AUTOSAR XML (schema 00046)
package /ComponentTypes
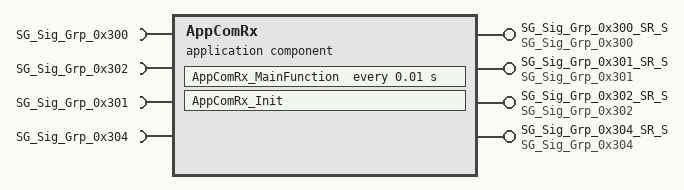
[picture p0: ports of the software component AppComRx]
  application sw component type AppComRx
    4 x require port:
      SG_Sig_Grp_0x300: nonqueued-receiver-com-spec{data-element=SG_Sig_Grp_0x300, init-value=fields=[D_Led1_Control:2, D_Led2_Control:2, D_Led3_Control:2, D_Led4_Control:2, SupD_Checksum_0x300:0, SupD_Counter_0x300:0]}, required-interface=SG_Sig_Grp_0x300
      SG_Sig_Grp_0x302: nonqueued-receiver-com-spec{data-element=SG_Sig_Grp_0x302, init-value=fields=[E_Sig_0x302_Used_1:0, E_Sig_0x302_Used_2:0, E_Sig_0x302_Used_3:0]}, required-interface=SG_Sig_Grp_0x302
      SG_Sig_Grp_0x301: nonqueued-receiver-com-spec{data-element=SG_Sig_Grp_0x301, init-value=fields=[D_Button1_Control:0, D_Button2_Control:0, D_Button3_Control:0, D_Button4_Control:0]}, required-interface=SG_Sig_Grp_0x301
      SG_Sig_Grp_0x304: nonqueued-receiver-com-spec{data-element=SG_Sig_Grp_0x304, init-value=fields=[D_Led1_CtrlMode:0, D_Led2_CtrlMode:0, D_Led3_CtrlMode:0, D_Led4_CtrlMode:0, SupD_Checksum_0x304:0, SupD_Counter_0x304:0]}, required-interface=SG_Sig_Grp_0x304
    4 x provide port:
      SG_Sig_Grp_0x300_SR_S: nonqueued-sender-com-spec{data-element=SG_Sig_Grp_0x300, init-value=fields=[D_Led1_Control:2, D_Led2_Control:2, D_Led3_Control:2, D_Led4_Control:2, SupD_Checksum_0x300:0, SupD_Counter_0x300:0]}, provided-interface=SG_Sig_Grp_0x300
      SG_Sig_Grp_0x301_SR_S: nonqueued-sender-com-spec{data-element=SG_Sig_Grp_0x301, init-value=fields=[D_Button1_Control:0, D_Button2_Control:0, D_Button3_Control:0, D_Button4_Control:0]}, provided-interface=SG_Sig_Grp_0x301
      SG_Sig_Grp_0x302_SR_S: nonqueued-sender-com-spec{data-element=SG_Sig_Grp_0x302, init-value=fields=[E_Sig_0x302_Used_1:0, E_Sig_0x302_Used_2:0, E_Sig_0x302_Used_3:0]}, provided-interface=SG_Sig_Grp_0x302
      SG_Sig_Grp_0x304_SR_S: nonqueued-sender-com-spec{data-element=SG_Sig_Grp_0x304, init-value=fields=[D_Led1_CtrlMode:0, D_Led2_CtrlMode:0, D_Led3_CtrlMode:0, D_Led4_CtrlMode:0, SupD_Checksum_0x304:0, SupD_Counter_0x304:0]}, provided-interface=SG_Sig_Grp_0x304
    behavior AppComRx_InternalBehavior
      init event AppComRx_InitEvent: start-on-event=AppComRx_Init
      timing event TMT_AppComRx_MainFunction: start-on-event=AppComRx_MainFunction, period=0.01
      runnable AppComRx_MainFunction
        data-receive-point-by-arguments:
          4 x access:
            REC_SG_Sig_Grp_0x{300..302}_SG_Sig_Grp_0x{300..302}: accessed-variable=SG_Sig_Grp_0x{300..302}.SG_Sig_Grp_0x{300..302}
            REC_SG_Sig_Grp_0x304_SG_Sig_Grp_0x304: accessed-variable=SG_Sig_Grp_0x304.SG_Sig_Grp_0x304
        data-send-points:
          4 x access:
            SEND_SG_Sig_Grp_0x{300..302}_SR_S_SG_Sig_Grp_0x{300..302}: accessed-variable=SG_Sig_Grp_0x{300..302}_SR_S.SG_Sig_Grp_0x{300..302}
            SEND_SG_Sig_Grp_0x304_SR_S_SG_Sig_Grp_0x304: accessed-variable=SG_Sig_Grp_0x304_SR_S.SG_Sig_Grp_0x304
      runnable AppComRx_Init
  swc implementation AppComRx_Implementation: behavior=AppComRx_InternalBehavior
